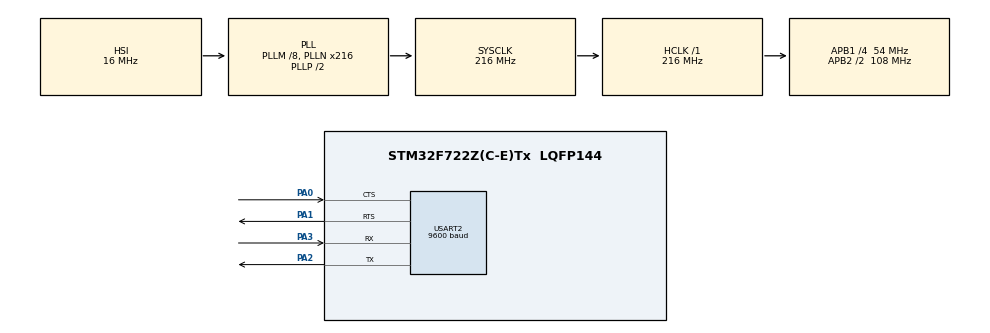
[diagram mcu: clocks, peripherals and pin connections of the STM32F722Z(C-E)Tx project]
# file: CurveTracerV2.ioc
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Mcu.Family=STM32F7
Mcu.Name=STM32F722Z(C-E)Tx
Mcu.Package=LQFP144
NVIC.PriorityGroup=NVIC_PRIORITYGROUP_4
NVIC.USART2_IRQn=true\:0\:0\:false\:false\:true\:true\:true
PA0-WKUP.Mode=CTS_RTS
PA0-WKUP.Signal=USART2_CTS
PA1.Mode=CTS_RTS
PA1.Signal=USART2_RTS
PA13.Mode=JTAG_5_pins
PA13.Signal=SYS_JTMS-SWDIO
PA14.Mode=JTAG_5_pins
PA14.Signal=SYS_JTCK-SWCLK
PA15.Mode=JTAG_5_pins
PA15.Signal=SYS_JTDI
PA2.Mode=Asynchronous
PA2.Signal=USART2_TX
PA3.Mode=Asynchronous
PA3.Signal=USART2_RX
PB3.Mode=JTAG_5_pins
PB3.Signal=SYS_JTDO-SWO
PB4.Mode=JTAG_5_pins
PB4.Signal=SYS_JTRST
ProjectManager.HeapSize=0x200
ProjectManager.StackSize=0x400
ProjectManager.TargetToolchain=STM32CubeIDE
RCC.AHBFreq_Value=216000000
RCC.APB1CLKDivider=RCC_HCLK_DIV4
RCC.APB1Freq_Value=54000000
RCC.APB1TimFreq_Value=108000000
RCC.APB2CLKDivider=RCC_HCLK_DIV2
RCC.APB2Freq_Value=108000000
RCC.APB2TimFreq_Value=216000000
RCC.CortexFreq_Value=216000000
RCC.HCLKFreq_Value=216000000
RCC.HSE_VALUE=25000000
RCC.HSI_VALUE=16000000
RCC.LSE_VALUE=32768
RCC.PLLM=8
RCC.PLLN=216
RCC.SYSCLKFreq_VALUE=216000000
RCC.SYSCLKSource=RCC_SYSCLKSOURCE_PLLCLK
RCC.USBFreq_Value=216000000
RCC.VCOOutputFreq_Value=432000000
USART2.BaudRate=9600
USART2.MSBFirstParam=ADVFEATURE_MSBFIRST_ENABLE
USART2.OverSampling=UART_OVERSAMPLING_8
USART2.VirtualMode-Asynchronous=VM_ASYNC
board=custom

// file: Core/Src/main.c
/* USER CODE BEGIN Header */
/**
 ******************************************************************************
 * @file           : main.c
 * @brief          : Main program body
 ******************************************************************************
 * @attention
 *
 * <h2><center>&copy; Copyright (c) 2020 STMicroelectronics.
 * All rights reserved.</center></h2>
 *
 * This software component is licensed by ST under BSD 3-Clause license,
 * the "License"; You may not use this file except in compliance with the
 * License. You may obtain a copy of the License at:
 *                        opensource.org/licenses/BSD-3-Clause
 *
 ******************************************************************************
 */
/* USER CODE END Header */
#include "main.h"
#include "ublox.h"

UART_HandleTypeDef huart2;

void SystemClock_Config(void);
static void MX_GPIO_Init(void);
static void MX_USART2_UART_Init(void);

/* USER CODE BEGIN PFP */
// AT Commands
HAL_StatusTypeDef sender;
HAL_StatusTypeDef receiver;
/* USER CODE END PFP */

int main(void)
{

  /* MCU Configuration--------------------------------------------------------*/

  /* Reset of all peripherals, Initializes the Flash interface and the Systick. */
  HAL_Init();

  /* Configure the system clock */
  SystemClock_Config();

  /* Initialize all configured peripherals */
  MX_GPIO_Init();
  MX_USART2_UART_Init();
  /* USER CODE BEGIN 2 */
  ublox_setup();
  /* USER CODE END 2 */

  /* Infinite loop */
	while (1)
	{

	}
}

void SystemClock_Config(void)
{
  RCC_OscInitTypeDef RCC_OscInitStruct = {0};
  RCC_ClkInitTypeDef RCC_ClkInitStruct = {0};
  RCC_PeriphCLKInitTypeDef PeriphClkInitStruct = {0};

  /** Configure the main internal regulator output voltage
  */
  __HAL_RCC_PWR_CLK_ENABLE();
  __HAL_PWR_VOLTAGESCALING_CONFIG(PWR_REGULATOR_VOLTAGE_SCALE1);
  /** Initializes the RCC Oscillators according to the specified parameters
  * in the RCC_OscInitTypeDef structure.
  */
  RCC_OscInitStruct.OscillatorType = RCC_OSCILLATORTYPE_HSI;
  RCC_OscInitStruct.HSIState = RCC_HSI_ON;
  RCC_OscInitStruct.HSICalibrationValue = RCC_HSICALIBRATION_DEFAULT;
  RCC_OscInitStruct.PLL.PLLState = RCC_PLL_ON;
  RCC_OscInitStruct.PLL.PLLSource = RCC_PLLSOURCE_HSI;
  RCC_OscInitStruct.PLL.PLLM = 8;
  RCC_OscInitStruct.PLL.PLLN = 216;
  RCC_OscInitStruct.PLL.PLLP = RCC_PLLP_DIV2;
  RCC_OscInitStruct.PLL.PLLQ = 2;
  if (HAL_RCC_OscConfig(&RCC_OscInitStruct) != HAL_OK)
  {
    Error_Handler();
  }
  /** Activate the Over-Drive mode
  */
  if (HAL_PWREx_EnableOverDrive() != HAL_OK)
  {
    Error_Handler();
  }
  /** Initializes the CPU, AHB and APB buses clocks
  */
  RCC_ClkInitStruct.ClockType = RCC_CLOCKTYPE_HCLK|RCC_CLOCKTYPE_SYSCLK
                              |RCC_CLOCKTYPE_PCLK1|RCC_CLOCKTYPE_PCLK2;
  RCC_ClkInitStruct.SYSCLKSource = RCC_SYSCLKSOURCE_PLLCLK;
  RCC_ClkInitStruct.AHBCLKDivider = RCC_SYSCLK_DIV1;
  RCC_ClkInitStruct.APB1CLKDivider = RCC_HCLK_DIV4;
  RCC_ClkInitStruct.APB2CLKDivider = RCC_HCLK_DIV2;

  if (HAL_RCC_ClockConfig(&RCC_ClkInitStruct, FLASH_LATENCY_7) != HAL_OK)
  {
    Error_Handler();
  }
  PeriphClkInitStruct.PeriphClockSelection = RCC_PERIPHCLK_USART2;
  PeriphClkInitStruct.Usart2ClockSelection = RCC_USART2CLKSOURCE_PCLK1;
  if (HAL_RCCEx_PeriphCLKConfig(&PeriphClkInitStruct) != HAL_OK)
  {
    Error_Handler();
  }
}

static void MX_USART2_UART_Init(void)
{

  huart2.Instance = USART2;
  huart2.Init.BaudRate = 115200;
  huart2.Init.WordLength = UART_WORDLENGTH_8B;
  huart2.Init.StopBits = UART_STOPBITS_1;
  huart2.Init.Parity = UART_PARITY_NONE;
  huart2.Init.Mode = UART_MODE_TX_RX;
  huart2.Init.HwFlowCtl = UART_HWCONTROL_RTS_CTS;
  huart2.Init.OverSampling = UART_OVERSAMPLING_8;
  huart2.Init.OneBitSampling = UART_ONE_BIT_SAMPLE_DISABLE;
  huart2.AdvancedInit.AdvFeatureInit = UART_ADVFEATURE_MSBFIRST_INIT;
  huart2.AdvancedInit.MSBFirst = UART_ADVFEATURE_MSBFIRST_DISABLE;
  if (HAL_UART_Init(&huart2) != HAL_OK)
  {
    Error_Handler();
  }

}

static void MX_GPIO_Init(void)
{

  /* GPIO Ports Clock Enable */
  __HAL_RCC_GPIOA_CLK_ENABLE();
  __HAL_RCC_GPIOB_CLK_ENABLE();

}

void Error_Handler(void)
{
}

/************************ (C) COPYRIGHT STMicroelectronics *****END OF FILE****/
